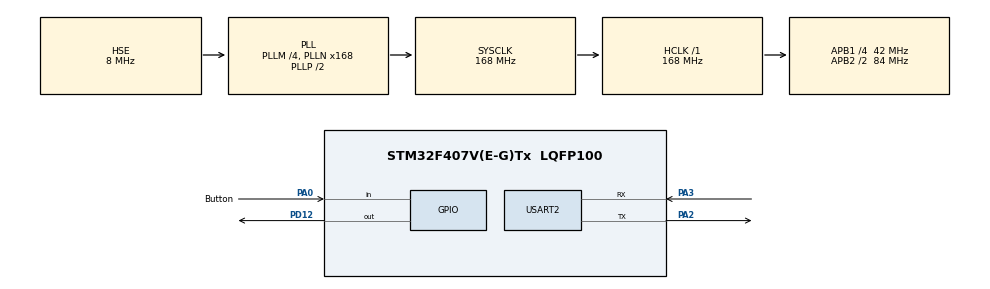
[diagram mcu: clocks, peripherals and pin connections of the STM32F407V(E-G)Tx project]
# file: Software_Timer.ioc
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Mcu.Family=STM32F4
RCC.PLLSourceVirtual=RCC_PLLSOURCE_HSE
VP_SYS_VS_tim6.Mode=TIM6
PH0-OSC_IN.Signal=RCC_OSC_IN
RCC.CortexFreq_Value=168000000
FREERTOS.Tasks01=UartTask,0,128,StartUartTask,Default,NULL,Dynamic,NULL,NULL;LedTask,0,128,StartLedTask,Default,NULL,Dynamic,NULL,NULL
NVIC.TIM6_DAC_IRQn=true\:0\:0\:false\:false\:true\:false\:false\:true
RCC.APB1CLKDivider=RCC_HCLK_DIV4
RCC.SYSCLKSource=RCC_SYSCLKSOURCE_PLLCLK
ProjectManager.StackSize=0x400
PA0-WKUP.GPIO_Label=Button
PA0-WKUP.Signal=GPIO_Input
PA3.Mode=Asynchronous
ProjectManager.TargetToolchain=STM32CubeIDE
RCC.HCLKFreq_Value=168000000
RCC.APB2TimFreq_Value=168000000
RCC.LSE_VALUE=32768
RCC.AHBFreq_Value=168000000
PH0-OSC_IN.Mode=HSE-External-Oscillator
RCC.HSE_VALUE=8000000
FREERTOS.configUSE_TIMERS=1
board=STM32F407G-DISC1
RCC.VCOOutputFreq_Value=336000000
RCC.APB2Freq_Value=84000000
PH1-OSC_OUT.Signal=RCC_OSC_OUT
VP_FREERTOS_VS_CMSIS_V1.Mode=CMSIS_V1
Mcu.Name=STM32F407V(E-G)Tx
FREERTOS.configTIMER_TASK_PRIORITY=6
PA2.Signal=USART2_TX
PH1-OSC_OUT.Mode=HSE-External-Oscillator
RCC.48MHZClocksFreq_Value=48000000
RCC.SYSCLKFreq_VALUE=168000000
Mcu.Package=LQFP100
NVIC.TimeBase=TIM6_DAC_IRQn
USART2.VirtualMode=VM_ASYNC
PD12.Signal=GPIO_Output
NVIC.TimeBaseIP=TIM6
ProjectManager.HeapSize=0x200
FREERTOS.Timers01=PeriodicTimer,PTCallback,osTimerPeriodic,Default,NULL,Dynamic,NULL;OnceTimer,OTCallback,osTimerPeriodic,Default,NULL,Dynamic,NULL
RCC.HSI_VALUE=16000000
RCC.PLLQ=7
NVIC.PriorityGroup=NVIC_PRIORITYGROUP_4
RCC.APB2CLKDivider=RCC_HCLK_DIV2
RCC.PLLM=4
RCC.PLLN=168
RCC.APB1TimFreq_Value=84000000
PA2.Mode=Asynchronous
RCC.APB1Freq_Value=42000000
PA3.Signal=USART2_RX

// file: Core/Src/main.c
/* USER CODE BEGIN Header */
/**
  ******************************************************************************
  * @file           : main.c
  * @brief          : Main program body
  ******************************************************************************
  * @attention
  *
  * <h2><center>&copy; Copyright (c) 2021 STMicroelectronics.
  * All rights reserved.</center></h2>
  *
  * This software component is licensed by ST under BSD 3-Clause license,
  * the "License"; You may not use this file except in compliance with the
  * License. You may obtain a copy of the License at:
  *                        opensource.org/licenses/BSD-3-Clause
  *
  ******************************************************************************
  */
/* USER CODE END Header */
#include "main.h"
#include "cmsis_os.h"

UART_HandleTypeDef huart2;

osThreadId UartTaskHandle;
osThreadId LedTaskHandle;
osTimerId PeriodicTimerHandle;
osTimerId OnceTimerHandle;

void SystemClock_Config(void);
static void MX_GPIO_Init(void);
static void MX_USART2_UART_Init(void);
void StartUartTask(void const * argument);
void StartLedTask(void const * argument);
void PTCallback(void const * argument);
void OTCallback(void const * argument);

int main(void)
{

  /* MCU Configuration--------------------------------------------------------*/

  /* Reset of all peripherals, Initializes the Flash interface and the Systick. */
  HAL_Init();

  /* Configure the system clock */
  SystemClock_Config();

  /* Initialize all configured peripherals */
  MX_GPIO_Init();
  MX_USART2_UART_Init();

  /* Create the timer(s) */
  /* definition and creation of PeriodicTimer */
  osTimerDef(PeriodicTimer, PTCallback);
  PeriodicTimerHandle = osTimerCreate(osTimer(PeriodicTimer), osTimerPeriodic, NULL);

  /* definition and creation of OnceTimer */
  osTimerDef(OnceTimer, OTCallback);
  OnceTimerHandle = osTimerCreate(osTimer(OnceTimer), osTimerPeriodic, NULL);

  /* Create the thread(s) */
  /* definition and creation of UartTask */
  osThreadDef(UartTask, StartUartTask, osPriorityNormal, 0, 128);
  UartTaskHandle = osThreadCreate(osThread(UartTask), NULL);

  /* definition and creation of LedTask */
  osThreadDef(LedTask, StartLedTask, osPriorityNormal, 0, 128);
  LedTaskHandle = osThreadCreate(osThread(LedTask), NULL);

  /* Start scheduler */
  osKernelStart();

  /* We should never get here as control is now taken by the scheduler */
  /* Infinite loop */
  while (1)
  {

  }
}

void SystemClock_Config(void)
{
  RCC_OscInitTypeDef RCC_OscInitStruct = {0};
  RCC_ClkInitTypeDef RCC_ClkInitStruct = {0};

  /** Configure the main internal regulator output voltage
  */
  __HAL_RCC_PWR_CLK_ENABLE();
  __HAL_PWR_VOLTAGESCALING_CONFIG(PWR_REGULATOR_VOLTAGE_SCALE1);
  /** Initializes the RCC Oscillators according to the specified parameters
  * in the RCC_OscInitTypeDef structure.
  */
  RCC_OscInitStruct.OscillatorType = RCC_OSCILLATORTYPE_HSE;
  RCC_OscInitStruct.HSEState = RCC_HSE_ON;
  RCC_OscInitStruct.PLL.PLLState = RCC_PLL_ON;
  RCC_OscInitStruct.PLL.PLLSource = RCC_PLLSOURCE_HSE;
  RCC_OscInitStruct.PLL.PLLM = 4;
  RCC_OscInitStruct.PLL.PLLN = 168;
  RCC_OscInitStruct.PLL.PLLP = RCC_PLLP_DIV2;
  RCC_OscInitStruct.PLL.PLLQ = 7;
  if (HAL_RCC_OscConfig(&RCC_OscInitStruct) != HAL_OK)
  {
    Error_Handler();
  }
  /** Initializes the CPU, AHB and APB buses clocks
  */
  RCC_ClkInitStruct.ClockType = RCC_CLOCKTYPE_HCLK|RCC_CLOCKTYPE_SYSCLK
                              |RCC_CLOCKTYPE_PCLK1|RCC_CLOCKTYPE_PCLK2;
  RCC_ClkInitStruct.SYSCLKSource = RCC_SYSCLKSOURCE_PLLCLK;
  RCC_ClkInitStruct.AHBCLKDivider = RCC_SYSCLK_DIV1;
  RCC_ClkInitStruct.APB1CLKDivider = RCC_HCLK_DIV4;
  RCC_ClkInitStruct.APB2CLKDivider = RCC_HCLK_DIV2;

  if (HAL_RCC_ClockConfig(&RCC_ClkInitStruct, FLASH_LATENCY_5) != HAL_OK)
  {
    Error_Handler();
  }
}

static void MX_USART2_UART_Init(void)
{

  huart2.Instance = USART2;
  huart2.Init.BaudRate = 115200;
  huart2.Init.WordLength = UART_WORDLENGTH_8B;
  huart2.Init.StopBits = UART_STOPBITS_1;
  huart2.Init.Parity = UART_PARITY_NONE;
  huart2.Init.Mode = UART_MODE_TX_RX;
  huart2.Init.HwFlowCtl = UART_HWCONTROL_NONE;
  huart2.Init.OverSampling = UART_OVERSAMPLING_16;
  if (HAL_UART_Init(&huart2) != HAL_OK)
  {
    Error_Handler();
  }

}

static void MX_GPIO_Init(void)
{
  GPIO_InitTypeDef GPIO_InitStruct = {0};

  /* GPIO Ports Clock Enable */
  __HAL_RCC_GPIOH_CLK_ENABLE();
  __HAL_RCC_GPIOA_CLK_ENABLE();
  __HAL_RCC_GPIOD_CLK_ENABLE();

  /*Configure GPIO pin Output Level */
  HAL_GPIO_WritePin(GPIOD, GPIO_PIN_12, GPIO_PIN_RESET);

  /*Configure GPIO pin : Button_Pin */
  GPIO_InitStruct.Pin = Button_Pin;
  GPIO_InitStruct.Mode = GPIO_MODE_INPUT;
  GPIO_InitStruct.Pull = GPIO_NOPULL;
  HAL_GPIO_Init(Button_GPIO_Port, &GPIO_InitStruct);

  /*Configure GPIO pin : PD12 */
  GPIO_InitStruct.Pin = GPIO_PIN_12;
  GPIO_InitStruct.Mode = GPIO_MODE_OUTPUT_PP;
  GPIO_InitStruct.Pull = GPIO_NOPULL;
  GPIO_InitStruct.Speed = GPIO_SPEED_FREQ_LOW;
  HAL_GPIO_Init(GPIOD, &GPIO_InitStruct);

}

void StartUartTask(void const * argument)
{
  /* USER CODE BEGIN 5 */
	osTimerStart(PeriodicTimerHandle,1000);
  /* Infinite loop */
  for(;;)
  {
	  HAL_UART_Transmit(&huart2, (uint8_t*)"sending data from uart\n", 23, 100);
     osDelay(2000);
  }
  /* USER CODE END 5 */
}

void StartLedTask(void const * argument)
{
  /* USER CODE BEGIN StartLedTask */
  /* Infinite loop */
  for(;;)
  {
	  if((HAL_GPIO_ReadPin(Button_GPIO_Port, Button_Pin)))
	  {
		  HAL_UART_Transmit(&huart2, (uint8_t*)"switch is pressed \n", 23, 100);
		  HAL_GPIO_WritePin(GPIOD, GPIO_PIN_12, 1);
		  osTimerStart(OnceTimerHandle, 4000);
	  }
    osDelay(20);
  }
  /* USER CODE END StartLedTask */
}

/* PTCallback function */
void PTCallback(void const * argument)
{
  /* USER CODE BEGIN PTCallback */
	HAL_UART_Transmit(&huart2, (uint8_t* )"sending from PT\n", 23, 100);
  /* USER CODE END PTCallback */
}

/* OTCallback function */
void OTCallback(void const * argument)
{
  /* USER CODE BEGIN OTCallback */
	HAL_GPIO_WritePin(GPIOD, GPIO_PIN_12, 0);
  /* USER CODE END OTCallback */
}

 /**
  * @brief  Period elapsed callback in non blocking mode
  * @note   This function is called  when TIM6 interrupt took place, inside
  * HAL_TIM_IRQHandler(). It makes a direct call to HAL_IncTick() to increment
  * a global variable "uwTick" used as application time base.
  * @param  htim : TIM handle
  * @retval None
  */
void HAL_TIM_PeriodElapsedCallback(TIM_HandleTypeDef *htim)
{
  if (htim->Instance == TIM6) {
    HAL_IncTick();
  }
}

void Error_Handler(void)
{
  __disable_irq();
  while (1)
  {
  }
}

/************************ (C) COPYRIGHT STMicroelectronics *****END OF FILE****/
